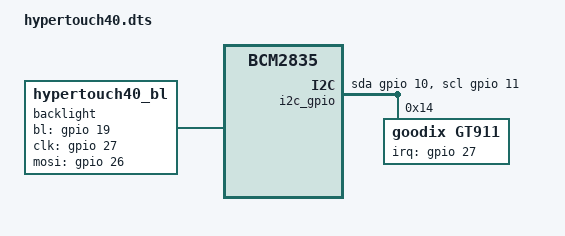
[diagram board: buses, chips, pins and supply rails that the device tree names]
/dts-v1/;
/plugin/;

/ {
    compatible = "brcm,bcm2835";

    fragment@0 {
        target = <&fb>;
        __overlay__ {
            pinctrl-names = "default";
            pinctrl-0 = <&dpi18_pins>;
        };
    };

    fragment@1 {
        target = <&gpio>;
        __overlay__ {
            dpi18_pins: dpi18_pins {
                brcm,pins = <0 1 2 3 4 5 6 7 8 9 12 13 14 15 16 17 20 21 22 23 24 25>;
                brcm,function = <6>; /* Alt2: DPI */
                brcm,pull = <0>; /* No pull */
            };
        };
    };

    fragment@2 {
        target-path = "/soc";
        __overlay__ {
            backlight: backlight {
                compatible = "hypertouch40_bl";
                bl-gpios = <&gpio 19 0>;
                clk-gpios = <&gpio 27 0>;
                mosi-gpios = <&gpio 26 0>;
                cs-gpios = <&gpio 18 0>;
            };
        };
    };

    /* Define the I2C-GPIO bus first */
    fragment@3 {
        target-path = "/";
        __overlay__ {
                        i2c_gpio: i2c@0 {
                            compatible = "i2c-gpio";
                            #address-cells = <1>;
                            #size-cells = <0>;
                            gpios = <&gpio 10 0 /* sda */
                                 &gpio 11 0 /* scl */
                                >;
                            i2c-gpio,delay-us = <4>;        /* ~100 kHz */                #address-cells = <1>;
                #size-cells = <0>;
                status = "okay";
            };
        };
    };

    /* Then add the Touch Device to the bus */
    fragment@4 {
        target = <&i2c_gpio>;
        __overlay__ {
            gt911: gt911@14 {
                compatible = "goodix,gt911";
                reg = <0x14>;
                interrupt-parent = <&gpio>;
                interrupts = <27 2>; /* IRQ_TYPE_EDGE_FALLING */
                /* 
                 * No reset-gpios: Reset is hardware pulled to 3.3V. 
                 * Address selection depends on GPIO 27 state at power-on.
                 */
                touchscreen-size-x = <480>;
                touchscreen-size-y = <800>;
                touchscreen-x-mm = <51>;
                touchscreen-y-mm = <85>;
                touchscreen-swapped-x-y;
            };
        };
    };

    __overrides__ {
        touchscreen-inverted-x = <&gt911>,"touchscreen-inverted-x";
        touchscreen-inverted-y = <&gt911>,"touchscreen-inverted-y";
        touchscreen-swapped-x-y = <&gt911>,"touchscreen-swapped-x-y";
        addr = <&gt911>,"reg:0";
    };
};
